# HC32F448 register map
File version: 1.0
CPU: CM4 r0p1, little endian, MPU, FPU, 4 interrupt priority bits
Registers are 32-bit, read-write, reset 0x0 unless marked. A register's access mark holds for its fields unless they carry their own. Offsets are from the block's base; [hi:lo] are bit positions; {n}, {i} and the like mark numbered series.

## DMA1 — desc DMA
Base 0x40053000
Same registers: DMA2 0x40053400
0x00 EN
  [0] EN
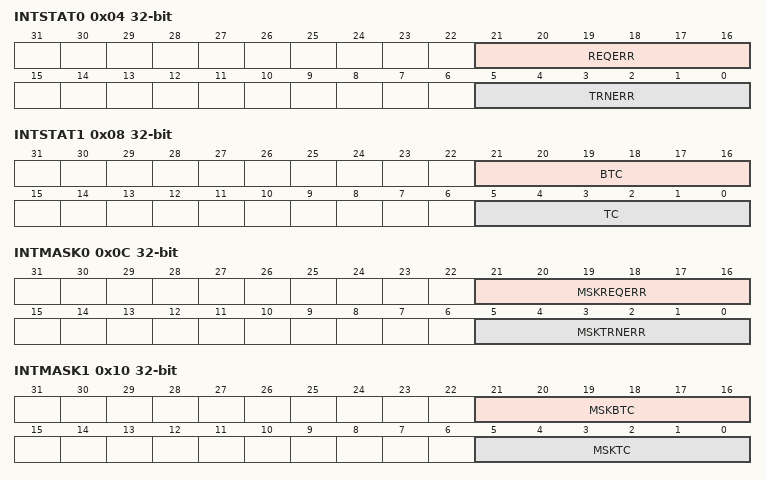
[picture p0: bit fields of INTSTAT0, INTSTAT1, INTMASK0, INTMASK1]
0x04 INTSTAT0 ro
  [21:16] REQERR, [5:0] TRNERR
0x08 INTSTAT1 ro
  [21:16] BTC, [5:0] TC
0x0C INTMASK0
  [21:16] MSKREQERR, [5:0] MSKTRNERR
0x10 INTMASK1
  [21:16] MSKBTC, [5:0] MSKTC
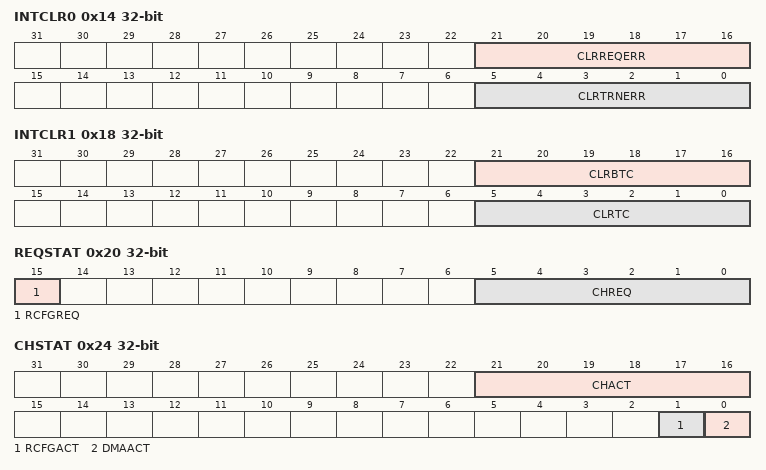
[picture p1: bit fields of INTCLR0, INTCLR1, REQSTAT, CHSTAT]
0x14 INTCLR0 wo
  [21:16] CLRREQERR, [5:0] CLRTRNERR
0x18 INTCLR1 wo
  [21:16] CLRBTC, [5:0] CLRTC
0x1C CHEN
  [5:0] CHEN
0x20 REQSTAT ro
  [15] RCFGREQ, [5:0] CHREQ
0x24 CHSTAT ro
  [21:16] CHACT, [1] RCFGACT, [0] DMAACT
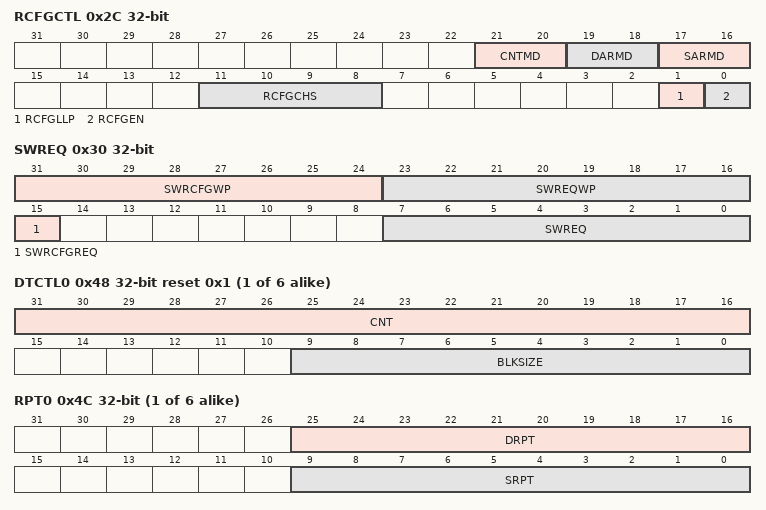
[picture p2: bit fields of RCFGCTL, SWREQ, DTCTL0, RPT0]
0x2C RCFGCTL
  [21:20] CNTMD, [19:18] DARMD, [17:16] SARMD, [11:8] RCFGCHS, [1] RCFGLLP, [0] RCFGEN
0x30 SWREQ wo
  [31:24] SWRCFGWP, [23:16] SWREQWP, [15] SWRCFGREQ, [7:0] SWREQ
0x34 CHENCLR wo
  [5:0] CHENCLR
{0x40+0x40*i} SAR{i} (i=0..5)
{0x44+0x40*i} DAR{i} (i=0..5)
{0x48+0x40*i} DTCTL{i} reset 0x1 (i=0..5)
  [31:16] CNT, [9:0] BLKSIZE
{0x4C+0x40*i} RPT{i} (i=0..5)
  [25:16] DRPT, [9:0] SRPT
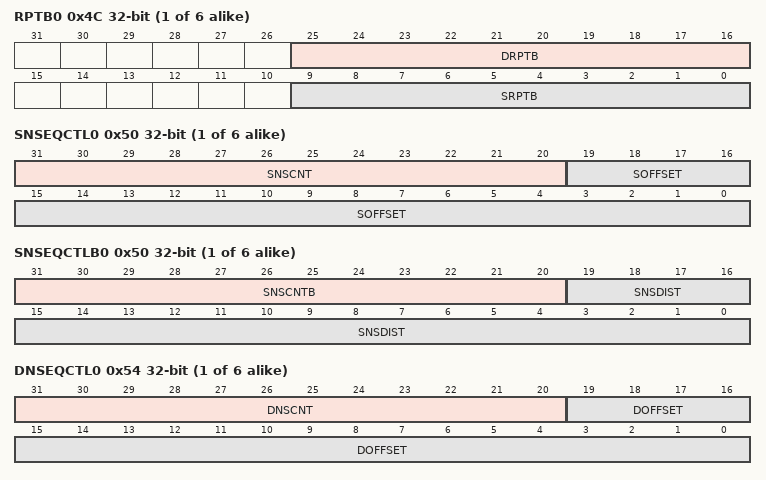
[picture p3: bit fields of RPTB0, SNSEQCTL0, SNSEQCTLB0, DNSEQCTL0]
{0x4C+0x40*i} RPTB{i} (alternate view of RPT{i}) (i=0..5)
  [25:16] DRPTB, [9:0] SRPTB
{0x50+0x40*i} SNSEQCTL{i} (i=0..5)
  [31:20] SNSCNT, [19:0] SOFFSET
{0x50+0x40*i} SNSEQCTLB{i} (alternate view of SNSEQCTL{i}) (i=0..5)
  [31:20] SNSCNTB, [19:0] SNSDIST
{0x54+0x40*i} DNSEQCTL{i} (i=0..5)
  [31:20] DNSCNT, [19:0] DOFFSET
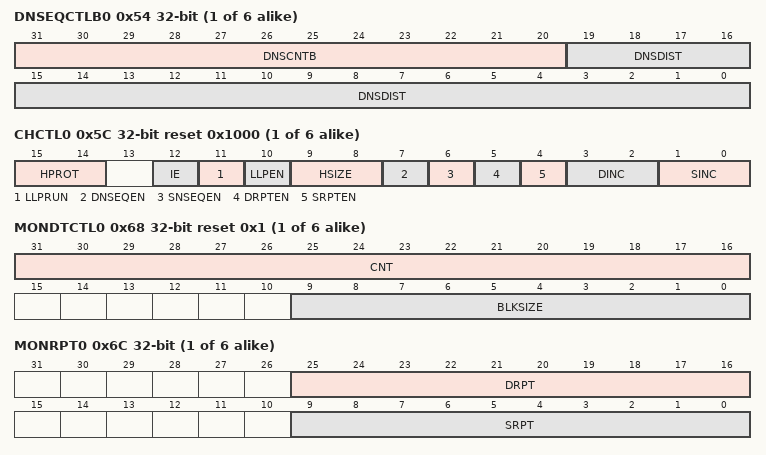
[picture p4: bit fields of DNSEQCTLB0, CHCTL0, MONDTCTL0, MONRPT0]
{0x54+0x40*i} DNSEQCTLB{i} (alternate view of DNSEQCTL{i}) (i=0..5)
  [31:20] DNSCNTB, [19:0] DNSDIST
{0x58+0x40*i} LLP{i} (i=0..5)
  [31:2] LLP
{0x5C+0x40*i} CHCTL{i} reset 0x1000 (i=0..5)
  [15:14] HPROT, [12] IE, [11] LLPRUN, [10] LLPEN, [9:8] HSIZE, [7] DNSEQEN, [6] SNSEQEN, [5] DRPTEN, [4] SRPTEN, [3:2] DINC, [1:0] SINC
{0x60+0x40*i} MONSAR{i} ro (i=0..5)
{0x64+0x40*i} MONDAR{i} ro (i=0..5)
{0x68+0x40*i} MONDTCTL{i} ro reset 0x1 (i=0..5)
  [31:16] CNT, [9:0] BLKSIZE
{0x6C+0x40*i} MONRPT{i} ro (i=0..5)
  [25:16] DRPT, [9:0] SRPT
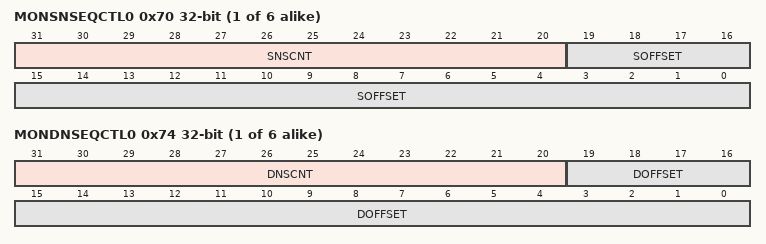
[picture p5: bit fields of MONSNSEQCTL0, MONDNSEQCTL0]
{0x70+0x40*i} MONSNSEQCTL{i} ro (i=0..5)
  [31:20] SNSCNT, [19:0] SOFFSET
{0x74+0x40*i} MONDNSEQCTL{i} ro (i=0..5)
  [31:20] DNSCNT, [19:0] DOFFSET

## EFM
Base 0x40010400
0x00 FAPRT
  [15:0] FAPRT
0x04 KEY1
0x08 KEY2
0x14 FSTP
  [0] FSTP
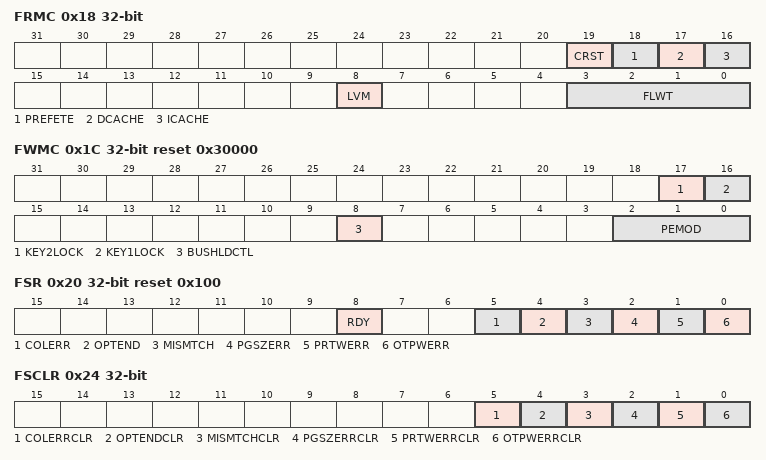
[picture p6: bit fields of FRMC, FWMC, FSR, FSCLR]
0x18 FRMC
  [19] CRST, [18] PREFETE, [17] DCACHE, [16] ICACHE, [8] LVM, [3:0] FLWT
0x1C FWMC reset 0x30000
  [17] KEY2LOCK, [16] KEY1LOCK, [8] BUSHLDCTL, [2:0] PEMOD
0x20 FSR ro reset 0x100
  [8] RDY, [5] COLERR, [4] OPTEND, [3] MISMTCH, [2] PGSZERR, [1] PRTWERR, [0] OTPWERR
0x24 FSCLR
  [5] COLERRCLR, [4] OPTENDCLR, [3] MISMTCHCLR, [2] PGSZERRCLR, [1] PRTWERRCLR, [0] OTPWERRCLR
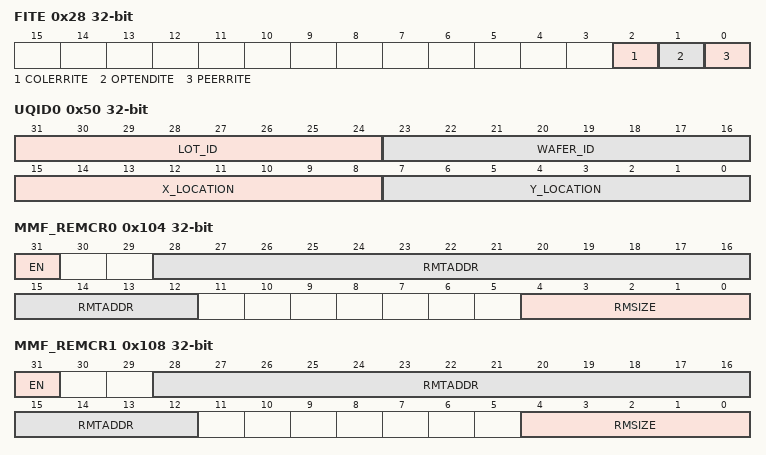
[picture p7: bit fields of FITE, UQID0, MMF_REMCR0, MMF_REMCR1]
0x28 FITE
  [2] COLERRITE, [1] OPTENDITE, [0] PEERRITE
0x2C FSWP ro
  [0] FSWP
0x40 CHIPID ro reset 0x58480448
0x50 UQID0 ro
  [31:24] LOT_ID, [23:16] WAFER_ID, [15:8] X_LOCATION, [7:0] Y_LOCATION
0x54 UQID1 ro
  [31:0] LOT_ID
0x58 UQID2 ro
  [7:0] LOT_ID
0x100 MMF_REMPRT
  [15:0] MMF_REMPRT
0x104 MMF_REMCR0
  [31] EN, [28:12] RMTADDR, [4:0] RMSIZE
0x108 MMF_REMCR1
  [31] EN, [28:12] RMTADDR, [4:0] RMSIZE
0x180 WLOCK
  [0] WLOCK0
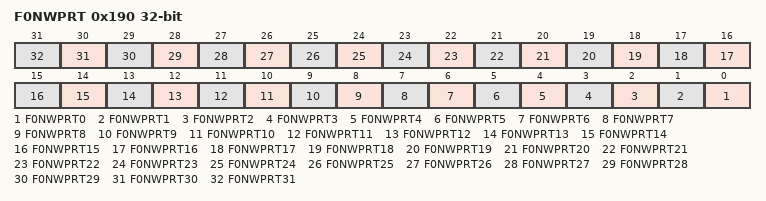
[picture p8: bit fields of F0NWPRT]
0x190 F0NWPRT
  [n] F0NWPRT{n} (n=0..31)

## EMB0
Base 0x40017C00
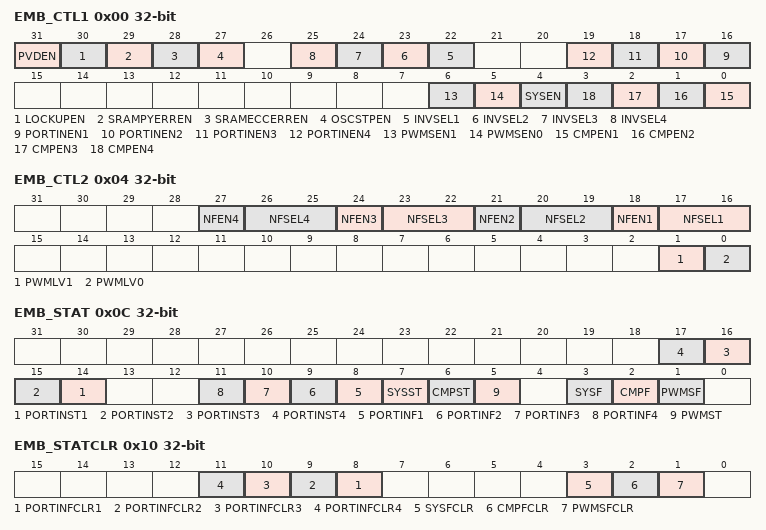
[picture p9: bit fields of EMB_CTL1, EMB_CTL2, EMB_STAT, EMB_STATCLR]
0x00 EMB_CTL1
  [31] PVDEN, [30] LOCKUPEN, [29] SRAMPYERREN, [28] SRAMECCERREN, [27] OSCSTPEN, [n+21] INVSEL{n} (n=1..4), [n+15] PORTINEN{n} (n=1..4), [6] PWMSEN1, [5] PWMSEN0, [4] SYSEN, [n-1] CMPEN{n} (n=1..4)
0x04 EMB_CTL2
  [3n+15] NFEN{n} (n=1..4), [3n+14:3n+13] NFSEL{n} (n=1..4), [1] PWMLV1, [0] PWMLV0
0x08 EMB_SOE
  [0] SOE
0x0C EMB_STAT ro
  [n+13] PORTINST{n} (n=1..4), [n+7] PORTINF{n} (n=1..4), [7] SYSST, [6] CMPST, [5] PWMST, [3] SYSF, [2] CMPF, [1] PWMSF
0x10 EMB_STATCLR wo
  [n+7] PORTINFCLR{n} (n=1..4), [3] SYSFCLR, [2] CMPFCLR, [1] PWMSFCLR
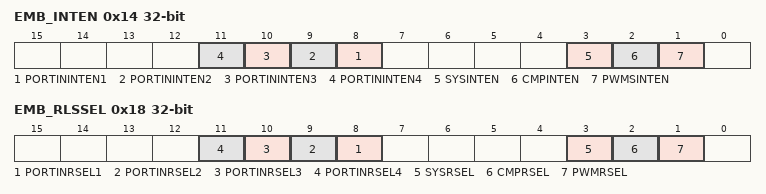
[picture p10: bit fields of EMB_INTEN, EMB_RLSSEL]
0x14 EMB_INTEN
  [n+7] PORTININTEN{n} (n=1..4), [3] SYSINTEN, [2] CMPINTEN, [1] PWMSINTEN
0x18 EMB_RLSSEL
  [n+7] PORTINRSEL{n} (n=1..4), [3] SYSRSEL, [2] CMPRSEL, [1] PWMRSEL
